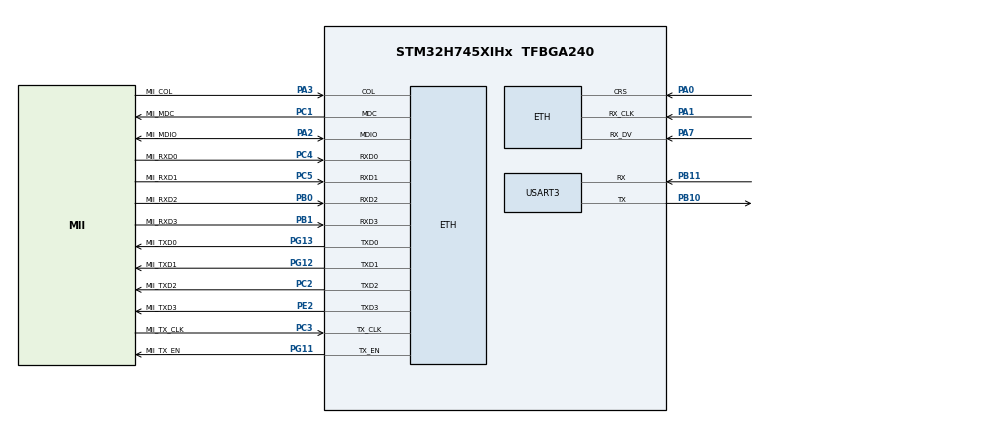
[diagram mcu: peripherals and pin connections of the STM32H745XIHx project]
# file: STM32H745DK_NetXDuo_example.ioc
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CORTEX_M7.AccessPermission_S-Cortex_Memory_Protection_Unit_Region1_Settings_S=MPU_REGION_FULL_ACCESS
CORTEX_M7.AccessPermission_S-Cortex_Memory_Protection_Unit_Region2_Settings_S=MPU_REGION_FULL_ACCESS
CORTEX_M7.BaseAddress_S-Cortex_Memory_Protection_Unit_Region1_Settings_S=0x30000000
CORTEX_M7.BaseAddress_S-Cortex_Memory_Protection_Unit_Region2_Settings_S=0x30000000
CORTEX_M7.CPU_DCache=Enabled
CORTEX_M7.CPU_ICache=Enabled
CORTEX_M7.Enable_S-Cortex_Memory_Protection_Unit_Region1_Settings_S=MPU_REGION_ENABLE
CORTEX_M7.Enable_S-Cortex_Memory_Protection_Unit_Region2_Settings_S=MPU_REGION_ENABLE
CORTEX_M7.IsBufferable_S-Cortex_Memory_Protection_Unit_Region2_Settings_S=MPU_ACCESS_BUFFERABLE
CORTEX_M7.IsCacheable_S-Cortex_Memory_Protection_Unit_Region1_Settings_S=MPU_ACCESS_NOT_CACHEABLE
CORTEX_M7.Size_S-Cortex_Memory_Protection_Unit_Region1_Settings_S=MPU_REGION_SIZE_64KB
CORTEX_M7.Size_S-Cortex_Memory_Protection_Unit_Region2_Settings_S=MPU_REGION_SIZE_256B
CORTEX_M7.TypeExtField_S-Cortex_Memory_Protection_Unit_Region1_Settings_S=MPU_TEX_LEVEL1
CortexM4.IPs=CORTEX_M4\:I,DEBUG,FATFS_M4\:I,FREERTOS_M4\:I,IWDG2\:I,OPENAMP_M4\:I,PDM2PCM_M4\:I,PWR,RCC,RESMGR_UTILITY,SYS_M4\:I,USB_DEVICE_M4\:I,USB_HOST_M4\:I,VREFBUF,WWDG2\:I,GPIO,DMA,BDMA,MDMA,NVIC2\:I,TIM7\:I
CortexM7.IPs=CORTEX_M7\:I,DEBUG\:I,FATFS_M7\:I,FREERTOS_M7\:I,IWDG1\:I,OPENAMP_M7\:I,PDM2PCM_M7\:I,PWR\:I,RCC\:I,RESMGR_UTILITY\:I,SYS\:I,USB_DEVICE_M7\:I,USB_HOST_M7\:I,VREFBUF\:I,WWDG1\:I,GPIO\:I,DMA\:I,BDMA\:I,MDMA\:I,NVIC1\:I,ETH\:I,USART3\:I,STMicroelectronics.X-CUBE-AZRTOS-H7.2.1.0_M7\:I,TIM6\:I
ETH.MACAddr=00\:80\:E1\:00\:30\:20
ETH.MediaInterface=HAL_ETH_MII_MODE
ETH.RxBuffLen=1536
ETH.RxDescAddress=0x30000000
ETH.TxDescAddress=0x30000060
Mcu.Family=STM32H7
Mcu.Name=STM32H745XIHx
Mcu.Package=TFBGA240
NVIC1.ETH_IRQn=true\:0\:0\:false\:false\:true\:false\:true\:true\:true
NVIC1.PriorityGroup=NVIC_PRIORITYGROUP_4
NVIC1.TIM6_DAC_IRQn=true\:15\:0\:false\:false\:true\:false\:false\:true\:true
NVIC1.TimeBase=TIM6_DAC_IRQn
NVIC1.TimeBaseIP=TIM6
NVIC2.PriorityGroup=NVIC_PRIORITYGROUP_4
NVIC2.TIM7_IRQn=true\:15\:0\:false\:false\:true\:false\:true\:true
NVIC2.TimeBase=TIM7_IRQn
NVIC2.TimeBaseIP=TIM7
PA0.GPIO_Speed=GPIO_SPEED_FREQ_VERY_HIGH
PA0.Mode=MII
PA0.PinAttribute=CortexM7
PA0.Signal=ETH_CRS
PA1.GPIO_Speed=GPIO_SPEED_FREQ_VERY_HIGH
PA1.Mode=MII
PA1.PinAttribute=CortexM7
PA1.Signal=ETH_RX_CLK
PA2.GPIO_Label=MII_MDIO
PA2.GPIO_Speed=GPIO_SPEED_FREQ_VERY_HIGH
PA2.Mode=MII
PA2.PinAttribute=CortexM7
PA2.Signal=ETH_MDIO
PA3.GPIO_Label=MII_COL
PA3.GPIO_Speed=GPIO_SPEED_FREQ_VERY_HIGH
PA3.Mode=MII
PA3.PinAttribute=CortexM7
PA3.Signal=ETH_COL
PA7.GPIO_Speed=GPIO_SPEED_FREQ_VERY_HIGH
PA7.Mode=MII
PA7.PinAttribute=CortexM7
PA7.Signal=ETH_RX_DV
PB0.GPIO_Label=MII_RXD2
PB0.GPIO_Speed=GPIO_SPEED_FREQ_VERY_HIGH
PB0.Mode=MII
PB0.PinAttribute=CortexM7
PB0.Signal=ETH_RXD2
PB1.GPIO_Label=MII_RXD3
PB1.GPIO_Speed=GPIO_SPEED_FREQ_VERY_HIGH
PB1.Mode=MII
PB1.PinAttribute=CortexM7
PB1.Signal=ETH_RXD3
PB10.Mode=Asynchronous
PB10.PinAttribute=CortexM7
PB10.Signal=USART3_TX
PB11.Mode=Asynchronous
PB11.PinAttribute=CortexM7
PB11.Signal=USART3_RX
PC1.GPIO_Label=MII_MDC
PC1.GPIO_Speed=GPIO_SPEED_FREQ_VERY_HIGH
PC1.Mode=MII
PC1.PinAttribute=CortexM7
PC1.Signal=ETH_MDC
PC2.GPIO_Label=MII_TXD2
PC2.GPIO_Speed=GPIO_SPEED_FREQ_VERY_HIGH
PC2.Mode=MII
PC2.PinAttribute=CortexM7
PC2.Signal=ETH_TXD2
PC3.GPIO_Label=MII_TX_CLK
PC3.GPIO_Speed=GPIO_SPEED_FREQ_VERY_HIGH
PC3.Mode=MII
PC3.PinAttribute=CortexM7
PC3.Signal=ETH_TX_CLK
PC4.GPIO_Label=MII_RXD0
PC4.GPIO_Speed=GPIO_SPEED_FREQ_VERY_HIGH
PC4.Mode=MII
PC4.PinAttribute=CortexM7
PC4.Signal=ETH_RXD0
PC5.GPIO_Label=MII_RXD1
PC5.GPIO_Speed=GPIO_SPEED_FREQ_VERY_HIGH
PC5.Mode=MII
PC5.PinAttribute=CortexM7
PC5.Signal=ETH_RXD1
PE2.GPIO_Label=MII_TXD3
PE2.GPIO_Speed=GPIO_SPEED_FREQ_VERY_HIGH
PE2.Mode=MII
PE2.PinAttribute=CortexM7
PE2.Signal=ETH_TXD3
PG11.GPIO_Label=MII_TX_EN
PG11.GPIO_Speed=GPIO_SPEED_FREQ_VERY_HIGH
PG11.Mode=MII
PG11.PinAttribute=CortexM7
PG11.Signal=ETH_TX_EN
PG12.GPIO_Label=MII_TXD1
PG12.GPIO_Speed=GPIO_SPEED_FREQ_VERY_HIGH
PG12.Mode=MII
PG12.PinAttribute=CortexM7
PG12.Signal=ETH_TXD1
PG13.GPIO_Label=MII_TXD0
PG13.GPIO_Speed=GPIO_SPEED_FREQ_VERY_HIGH
PG13.Mode=MII
PG13.PinAttribute=CortexM7
PG13.Signal=ETH_TXD0
PH0-OSC_IN\ (PH0).Mode=HSE-External-Oscillator
PH0-OSC_IN\ (PH0).PinAttribute=CortexM7
PH0-OSC_IN\ (PH0).Signal=RCC_OSC_IN
PH1-OSC_OUT\ (PH1).Mode=HSE-External-Oscillator
PH1-OSC_OUT\ (PH1).PinAttribute=CortexM7
PH1-OSC_OUT\ (PH1).Signal=RCC_OSC_OUT
ProjectManager.HeapSize=M4-0x1000,M7-0x1000
ProjectManager.StackSize=M4-0x2000,M7-0x2000
ProjectManager.TargetToolchain=STM32CubeIDE
RCC.ADCFreq_Value=50390625
RCC.APB1Freq_Value=100000000
RCC.APB2Freq_Value=100000000
RCC.APB3Freq_Value=100000000
RCC.APB4Freq_Value=100000000
RCC.CortexFreq_Value=400000000
RCC.D1PPRE=RCC_APB3_DIV2
RCC.D2PPRE1=RCC_APB1_DIV2
RCC.D2PPRE2=RCC_APB2_DIV2
RCC.D3PPRE=RCC_APB4_DIV2
RCC.DIVM1=2
RCC.DIVN1=64
RCC.HCLKFreq_Value=200000000
RCC.HPRE=RCC_HCLK_DIV2
RCC.PLL2FRACN=0
RCC.PLL3FRACN=0
RCC.PLLFRACN=0
RCC.PLLSourceVirtual=RCC_PLLSOURCE_HSE
RCC.PWR_Regulator_Voltage_Scale=PWR_REGULATOR_VOLTAGE_SCALE1
RCC.SYSCLKFreq_VALUE=400000000
RCC.SYSCLKSource=RCC_SYSCLKSOURCE_PLLCLK
RCC.USBFreq_Value=400000000
STMicroelectronics.X-CUBE-AZRTOS-H7.2.1.0_IsAnAzureRtosMw=true
STMicroelectronics.X-CUBE-AZRTOS-H7.2.1.0_M7.InterfacesCcNetworkJjEthernetOoInterface=true
STMicroelectronics.X-CUBE-AZRTOS-H7.2.1.0_M7.InterfacesCcNetworkJjEthernetOoPhyOoInterface=LAN8742IiPhyIiInterface
STMicroelectronics.X-CUBE-AZRTOS-H7.2.1.0_M7.NX_APP_MEM_POOL_SIZE=1024*40
STMicroelectronics.X-CUBE-AZRTOS-H7.2.1.0_M7.NX_DISABLE_IPV6=true
STMicroelectronics.X-CUBE-AZRTOS-H7.2.1.0_M7.NX_DNS_MAX_RETRIES=10
STMicroelectronics.X-CUBE-AZRTOS-H7.2.1.0_M7.NX_ENABLE_INTERFACE_CAPABILITY=true
STMicroelectronics.X-CUBE-AZRTOS-H7.2.1.0_M7.NetXDuoCcNetworkJjNetXDuoJjAddonsOoDHCPOoClient=true
STMicroelectronics.X-CUBE-AZRTOS-H7.2.1.0_M7.NetXDuoCcNetworkJjNetXDuoJjNXOoCore=true
STMicroelectronics.X-CUBE-AZRTOS-H7.2.1.0_M7.STM32CubeIiBSPIiComponentsCcBoardOoPartJjETHPhyJjLAN8742=true
STMicroelectronics.X-CUBE-AZRTOS-H7.2.1.0_M7.ThreadXCcRTOSJjThreadXJjCore=true
SYS.userName=SYS_M7
USART3.VirtualMode-Asynchronous=VM_ASYNC
VP_STMicroelectronics.X-CUBE-AZRTOS-H7_M7_VS_BoardOoPartJjSTM32CubeIiBSPIiComponents_1.1.0_2.1.0.Mode=BoardOoPartJjSTM32CubeIiBSPIiComponents
VP_STMicroelectronics.X-CUBE-AZRTOS-H7_M7_VS_NetworkJjInterfaces_2.1.0_2.1.0.Mode=NetworkJjInterfaces
VP_STMicroelectronics.X-CUBE-AZRTOS-H7_M7_VS_NetworkJjNetXDuo_6.1.10_2.1.0.Mode=NetworkJjNetXDuo
VP_STMicroelectronics.X-CUBE-AZRTOS-H7_M7_VS_RTOSJjThreadX_6.1.10_2.1.0.Mode=RTOSJjThreadX
VP_SYS_M4_VS_tim7.Mode=TIM7
VP_SYS_VS_tim6.Mode=TIM6
board=custom

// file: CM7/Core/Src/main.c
/* USER CODE BEGIN Header */
/**
  ******************************************************************************
  * @file           : main.c
  * @brief          : Main program body
  ******************************************************************************
  * @attention
  *
  * Copyright (c) 2022 STMicroelectronics.
  * All rights reserved.
  *
  * This software is licensed under terms that can be found in the LICENSE file
  * in the root directory of this software component.
  * If no LICENSE file comes with this software, it is provided AS-IS.
  *
  ******************************************************************************
  */
/* USER CODE END Header */
#include "main.h"
#include "string.h"
#include "app_threadx.h"

/* USER CODE BEGIN PD */
#if defined ( __GNUC__) && !defined(__clang__)
#define PUTCHAR_PROTOTYPE int __io_putchar(int ch)
#else
#define PUTCHAR_PROTOTYPE int fputc(int ch, FILE *f)
#endif

#ifndef HSEM_ID_0
#define HSEM_ID_0 (0U) /* HW semaphore 0*/
#endif
/* USER CODE END PD */

#if defined ( __ICCARM__ ) /*!< IAR Compiler */
#pragma location=0x30000000
ETH_DMADescTypeDef  DMARxDscrTab[ETH_RX_DESC_CNT]; /* Ethernet Rx DMA Descriptors */
#pragma location=0x30000060
ETH_DMADescTypeDef  DMATxDscrTab[ETH_TX_DESC_CNT]; /* Ethernet Tx DMA Descriptors */

#elif defined ( __CC_ARM )  /* MDK ARM Compiler */

__attribute__((at(0x30000000))) ETH_DMADescTypeDef  DMARxDscrTab[ETH_RX_DESC_CNT]; /* Ethernet Rx DMA Descriptors */
__attribute__((at(0x30000060))) ETH_DMADescTypeDef  DMATxDscrTab[ETH_TX_DESC_CNT]; /* Ethernet Tx DMA Descriptors */

#elif defined ( __GNUC__ ) /* GNU Compiler */
ETH_DMADescTypeDef DMARxDscrTab[ETH_RX_DESC_CNT] __attribute__((section(".RxDecripSection"))); /* Ethernet Rx DMA Descriptors */
ETH_DMADescTypeDef DMATxDscrTab[ETH_TX_DESC_CNT] __attribute__((section(".TxDecripSection")));   /* Ethernet Tx DMA Descriptors */

#endif

ETH_TxPacketConfig TxConfig;

ETH_HandleTypeDef heth;

UART_HandleTypeDef huart3;

void SystemClock_Config(void);
static void MPU_Config(void);
static void MX_GPIO_Init(void);
static void MX_ETH_Init(void);
static void MX_USART3_UART_Init(void);

int main(void)
{
/* USER CODE BEGIN Boot_Mode_Sequence_0 */
  int32_t timeout;
/* USER CODE END Boot_Mode_Sequence_0 */

  /* MPU Configuration--------------------------------------------------------*/
  MPU_Config();

  /* Enable I-Cache---------------------------------------------------------*/
  SCB_EnableICache();

  /* Enable D-Cache---------------------------------------------------------*/
  SCB_EnableDCache();

/* USER CODE BEGIN Boot_Mode_Sequence_1 */
  /* Wait until CPU2 boots and enters in stop mode or timeout*/
  timeout = 0xFFFF;
  while((__HAL_RCC_GET_FLAG(RCC_FLAG_D2CKRDY) != RESET) && (timeout-- > 0));
  if ( timeout < 0 )
  {
  Error_Handler();
  }
/* USER CODE END Boot_Mode_Sequence_1 */
  /* MCU Configuration--------------------------------------------------------*/

  /* Reset of all peripherals, Initializes the Flash interface and the Systick. */
  HAL_Init();

  /* Configure the system clock */
  SystemClock_Config();
/* USER CODE BEGIN Boot_Mode_Sequence_2 */
/* When system initialization is finished, Cortex-M7 will release Cortex-M4 by means of
HSEM notification */
/*HW semaphore Clock enable*/
__HAL_RCC_HSEM_CLK_ENABLE();
/*Take HSEM */
HAL_HSEM_FastTake(HSEM_ID_0);
/*Release HSEM in order to notify the CPU2(CM4)*/
HAL_HSEM_Release(HSEM_ID_0,0);
/* wait until CPU2 wakes up from stop mode */
timeout = 0xFFFF;
while((__HAL_RCC_GET_FLAG(RCC_FLAG_D2CKRDY) == RESET) && (timeout-- > 0));
if ( timeout < 0 )
{
Error_Handler();
}
/* USER CODE END Boot_Mode_Sequence_2 */

  /* Initialize all configured peripherals */
  MX_GPIO_Init();
  MX_ETH_Init();
  MX_USART3_UART_Init();

  MX_ThreadX_Init();

  /* We should never get here as control is now taken by the scheduler */
  /* Infinite loop */
  while (1)
  {

  }
}

void SystemClock_Config(void)
{
  RCC_OscInitTypeDef RCC_OscInitStruct = {0};
  RCC_ClkInitTypeDef RCC_ClkInitStruct = {0};

  /** Supply configuration update enable
  */
  HAL_PWREx_ConfigSupply(PWR_DIRECT_SMPS_SUPPLY);

  /** Configure the main internal regulator output voltage
  */
  __HAL_PWR_VOLTAGESCALING_CONFIG(PWR_REGULATOR_VOLTAGE_SCALE1);

  while(!__HAL_PWR_GET_FLAG(PWR_FLAG_VOSRDY)) {}

  /** Initializes the RCC Oscillators according to the specified parameters
  * in the RCC_OscInitTypeDef structure.
  */
  RCC_OscInitStruct.OscillatorType = RCC_OSCILLATORTYPE_HSE;
  RCC_OscInitStruct.HSEState = RCC_HSE_ON;
  RCC_OscInitStruct.PLL.PLLState = RCC_PLL_ON;
  RCC_OscInitStruct.PLL.PLLSource = RCC_PLLSOURCE_HSE;
  RCC_OscInitStruct.PLL.PLLM = 2;
  RCC_OscInitStruct.PLL.PLLN = 64;
  RCC_OscInitStruct.PLL.PLLP = 2;
  RCC_OscInitStruct.PLL.PLLQ = 2;
  RCC_OscInitStruct.PLL.PLLR = 2;
  RCC_OscInitStruct.PLL.PLLRGE = RCC_PLL1VCIRANGE_3;
  RCC_OscInitStruct.PLL.PLLVCOSEL = RCC_PLL1VCOWIDE;
  RCC_OscInitStruct.PLL.PLLFRACN = 0;
  if (HAL_RCC_OscConfig(&RCC_OscInitStruct) != HAL_OK)
  {
    Error_Handler();
  }

  /** Initializes the CPU, AHB and APB buses clocks
  */
  RCC_ClkInitStruct.ClockType = RCC_CLOCKTYPE_HCLK|RCC_CLOCKTYPE_SYSCLK
                              |RCC_CLOCKTYPE_PCLK1|RCC_CLOCKTYPE_PCLK2
                              |RCC_CLOCKTYPE_D3PCLK1|RCC_CLOCKTYPE_D1PCLK1;
  RCC_ClkInitStruct.SYSCLKSource = RCC_SYSCLKSOURCE_PLLCLK;
  RCC_ClkInitStruct.SYSCLKDivider = RCC_SYSCLK_DIV1;
  RCC_ClkInitStruct.AHBCLKDivider = RCC_HCLK_DIV2;
  RCC_ClkInitStruct.APB3CLKDivider = RCC_APB3_DIV2;
  RCC_ClkInitStruct.APB1CLKDivider = RCC_APB1_DIV2;
  RCC_ClkInitStruct.APB2CLKDivider = RCC_APB2_DIV2;
  RCC_ClkInitStruct.APB4CLKDivider = RCC_APB4_DIV2;

  if (HAL_RCC_ClockConfig(&RCC_ClkInitStruct, FLASH_LATENCY_2) != HAL_OK)
  {
    Error_Handler();
  }
}

static void MX_ETH_Init(void)
{

   static uint8_t MACAddr[6];

  heth.Instance = ETH;
  MACAddr[0] = 0x00;
  MACAddr[1] = 0x80;
  MACAddr[2] = 0xE1;
  MACAddr[3] = 0x00;
  MACAddr[4] = 0x30;
  MACAddr[5] = 0x20;
  heth.Init.MACAddr = &MACAddr[0];
  heth.Init.MediaInterface = HAL_ETH_MII_MODE;
  heth.Init.TxDesc = DMATxDscrTab;
  heth.Init.RxDesc = DMARxDscrTab;
  heth.Init.RxBuffLen = 1536;

  if (HAL_ETH_Init(&heth) != HAL_OK)
  {
    Error_Handler();
  }

  memset(&TxConfig, 0 , sizeof(ETH_TxPacketConfig));
  TxConfig.Attributes = ETH_TX_PACKETS_FEATURES_CSUM | ETH_TX_PACKETS_FEATURES_CRCPAD;
  TxConfig.ChecksumCtrl = ETH_CHECKSUM_IPHDR_PAYLOAD_INSERT_PHDR_CALC;
  TxConfig.CRCPadCtrl = ETH_CRC_PAD_INSERT;

}

static void MX_USART3_UART_Init(void)
{

  huart3.Instance = USART3;
  huart3.Init.BaudRate = 115200;
  huart3.Init.WordLength = UART_WORDLENGTH_8B;
  huart3.Init.StopBits = UART_STOPBITS_1;
  huart3.Init.Parity = UART_PARITY_NONE;
  huart3.Init.Mode = UART_MODE_TX_RX;
  huart3.Init.HwFlowCtl = UART_HWCONTROL_NONE;
  huart3.Init.OverSampling = UART_OVERSAMPLING_16;
  huart3.Init.OneBitSampling = UART_ONE_BIT_SAMPLE_DISABLE;
  huart3.Init.ClockPrescaler = UART_PRESCALER_DIV1;
  huart3.AdvancedInit.AdvFeatureInit = UART_ADVFEATURE_NO_INIT;
  if (HAL_UART_Init(&huart3) != HAL_OK)
  {
    Error_Handler();
  }
  if (HAL_UARTEx_SetTxFifoThreshold(&huart3, UART_TXFIFO_THRESHOLD_1_8) != HAL_OK)
  {
    Error_Handler();
  }
  if (HAL_UARTEx_SetRxFifoThreshold(&huart3, UART_RXFIFO_THRESHOLD_1_8) != HAL_OK)
  {
    Error_Handler();
  }
  if (HAL_UARTEx_DisableFifoMode(&huart3) != HAL_OK)
  {
    Error_Handler();
  }

}

static void MX_GPIO_Init(void)
{

  /* GPIO Ports Clock Enable */
  __HAL_RCC_GPIOG_CLK_ENABLE();
  __HAL_RCC_GPIOE_CLK_ENABLE();
  __HAL_RCC_GPIOH_CLK_ENABLE();
  __HAL_RCC_GPIOC_CLK_ENABLE();
  __HAL_RCC_GPIOA_CLK_ENABLE();
  __HAL_RCC_GPIOB_CLK_ENABLE();

}

/* USER CODE BEGIN 4 */
/**
* @brief  Retargets the C library printf function to the USART.
* @param  None
* @retval None
*/
PUTCHAR_PROTOTYPE
{
  /* Place your implementation of fputc here */
  /* e.g. write a character to the USART3 and Loop until the end of transmission */
  HAL_UART_Transmit(&huart3, (uint8_t *)&ch, 1, 0xFFFF);

  return ch;
}

/**
* @brief  This function is executed in case of success.
* @retval None
*/
void Success_Handler(void)
{
  /* USER CODE BEGIN Success_Handler_Debug */
  //BSP_LED_Off(LED2);
  while(1)
  {
    //BSP_LED_Toggle(LED1);
    tx_thread_sleep(50);
  }
  /* USER CODE END Success_Handler_Debug */
}
/* USER CODE END 4 */

/* MPU Configuration */

void MPU_Config(void)
{
  MPU_Region_InitTypeDef MPU_InitStruct = {0};

  /* Disables the MPU */
  HAL_MPU_Disable();

  /** Initializes and configures the Region and the memory to be protected
  */
  MPU_InitStruct.Enable = MPU_REGION_ENABLE;
  MPU_InitStruct.Number = MPU_REGION_NUMBER0;
  MPU_InitStruct.BaseAddress = 0x0;
  MPU_InitStruct.Size = MPU_REGION_SIZE_4GB;
  MPU_InitStruct.SubRegionDisable = 0x87;
  MPU_InitStruct.TypeExtField = MPU_TEX_LEVEL0;
  MPU_InitStruct.AccessPermission = MPU_REGION_NO_ACCESS;
  MPU_InitStruct.DisableExec = MPU_INSTRUCTION_ACCESS_DISABLE;
  MPU_InitStruct.IsShareable = MPU_ACCESS_SHAREABLE;
  MPU_InitStruct.IsCacheable = MPU_ACCESS_NOT_CACHEABLE;
  MPU_InitStruct.IsBufferable = MPU_ACCESS_NOT_BUFFERABLE;

  HAL_MPU_ConfigRegion(&MPU_InitStruct);

  /** Initializes and configures the Region and the memory to be protected
  */
  MPU_InitStruct.Number = MPU_REGION_NUMBER1;
  MPU_InitStruct.BaseAddress = 0x30000000;
  MPU_InitStruct.Size = MPU_REGION_SIZE_64KB;
  MPU_InitStruct.SubRegionDisable = 0x0;
  MPU_InitStruct.TypeExtField = MPU_TEX_LEVEL1;
  MPU_InitStruct.AccessPermission = MPU_REGION_FULL_ACCESS;
  MPU_InitStruct.DisableExec = MPU_INSTRUCTION_ACCESS_ENABLE;
  MPU_InitStruct.IsShareable = MPU_ACCESS_NOT_SHAREABLE;

  HAL_MPU_ConfigRegion(&MPU_InitStruct);

  /** Initializes and configures the Region and the memory to be protected
  */
  MPU_InitStruct.Number = MPU_REGION_NUMBER2;
  MPU_InitStruct.Size = MPU_REGION_SIZE_256B;
  MPU_InitStruct.TypeExtField = MPU_TEX_LEVEL0;
  MPU_InitStruct.IsBufferable = MPU_ACCESS_BUFFERABLE;

  HAL_MPU_ConfigRegion(&MPU_InitStruct);
  /* Enables the MPU */
  HAL_MPU_Enable(MPU_PRIVILEGED_DEFAULT);

}

void HAL_TIM_PeriodElapsedCallback(TIM_HandleTypeDef *htim)
{
  if (htim->Instance == TIM6) {
    HAL_IncTick();
  }
}

void Error_Handler(void)
{
  __disable_irq();
  while (1)
  {
  }
}
